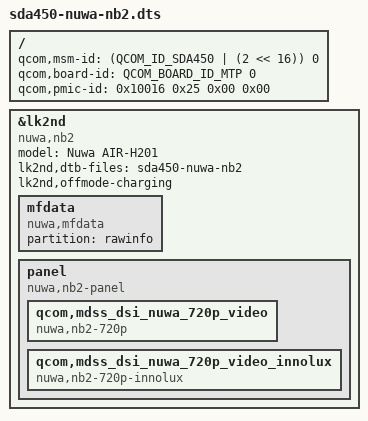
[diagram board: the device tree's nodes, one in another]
// SPDX-License-Identifier: BSD-3-Clause

/dts-v1/;

#include <skeleton64.dtsi>
#include <lk2nd.dtsi>

/ {
	/* Foundry ID 2: the bootloader skips its DTBO only on an exact match */
	qcom,msm-id = <(QCOM_ID_SDA450 | (2 << 16)) 0>;
	qcom,board-id = <QCOM_BOARD_ID_MTP 0>;
	qcom,pmic-id = <0x10016 0x25 0x00 0x00>;
};

&lk2nd {
	model = "Nuwa AIR-H201";
	compatible = "nuwa,nb2";

	lk2nd,dtb-files = "sda450-nuwa-nb2";
	lk2nd,offmode-charging;

	mfdata {
		compatible = "nuwa,mfdata";
		partition = "rawinfo";
	};

	panel {
		compatible = "nuwa,nb2-panel", "lk2nd,panel";

		qcom,mdss_dsi_nuwa_720p_video {
			compatible = "nuwa,nb2-720p";
		};
		qcom,mdss_dsi_nuwa_720p_video_innolux {
			compatible = "nuwa,nb2-720p-innolux";
		};
	};
};
